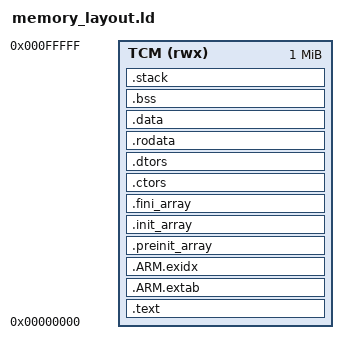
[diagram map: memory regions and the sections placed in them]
/****************************************************************************
 *                                                                          *
 *                         GNAT COMPILER COMPONENTS                         *
 *                                                                          *
 *                                  A R M                                   *
 *                                                                          *
 *                            Linker Script File                            *
 *                                                                          *
 *      Copyright (C) 1999-2002 Universidad Politecnica de Madrid           *
 *             Copyright (C) 2003-2006 The European Space Agency            *
 *                   Copyright (C) 2003-2018 AdaCore                        *
 *                                                                          *
 * GNAT is free software;  you can  redistribute it  and/or modify it under *
 * terms of the  GNU General Public License as published  by the Free Soft- *
 * ware  Foundation;  either version 2,  or (at your option) any later ver- *
 * sion.  GNAT is distributed in the hope that it will be useful, but WITH- *
 * OUT ANY WARRANTY;  without even the  implied warranty of MERCHANTABILITY *
 * or FITNESS FOR A PARTICULAR PURPOSE.  See the GNU General Public License *
 * for  more details.  You should have  received  a copy of the GNU General *
 * Public License  distributed with GNAT;  see file COPYING.  If not, write *
 * to  the  Free Software Foundation,  51  Franklin  Street,  Fifth  Floor, *
 * Boston, MA 02110-1301, USA.                                              *
 *                                                                          *
 * As a  special  exception,  if you  link  this file  with other  files to *
 * produce an executable,  this file does not by itself cause the resulting *
 * executable to be covered by the GNU General Public License. This except- *
 * ion does not  however invalidate  any other reasons  why the  executable *
 * file might be covered by the  GNU Public License.                        *
 *                                                                          *
 * GNARL was developed by the GNARL team at Florida State University.       *
 * Extensive contributions were provided by Ada Core Technologies, Inc.     *
 * The  executive  was developed  by the  Real-Time  Systems  Group  at the *
 * Technical University of Madrid.                                          *
 *                                                                          *
 ****************************************************************************/

ENTRY(reset_handler);

WORD_SIZE = 4;

MEMORY
{
  TCM(rwx) : ORIGIN = 0x00000000, LENGTH = 1024K
}

SECTIONS
{
 .text :
  {
    __mpu_global_text_region_start = .;

    KEEP (*(.text.hidden.interrupt_vector_table))

    *(.text.hidden.*)

    __hidden_text_end = .;
    __mpu_hidden_text_region_end = .;

    PROVIDE (_text_start = .);

   /* Functions that are the only ones allowed to enter privileged mode */
    __syscall_functions_start = .;
    *(.text.syscall.*)
    __syscall_functions_end = .;

    *(.text.unlikely .text.unlikely.*)
    *(.text.startup .text.startup.*)
    *(.text .text.*)
    *(.gnu.linkonce.t.*)
  } >TCM

  PROVIDE (__etext = .);
  PROVIDE (_etext = .);
  PROVIDE (etext = .);

  /*
   * ARM exception unwind table
   */
  .ARM.extab :
  {
    *(.ARM.extab* .gnu.linkonce.armextab.*)
  } >TCM

  /*
   * ARM exception unwind table index
   */
  .ARM.exidx :
  {
    PROVIDE_HIDDEN (__exidx_start = .);
    *(.ARM.exidx* .gnu.linkonce.armexidx.*)
    PROVIDE_HIDDEN (__exidx_end = .);
  } >TCM

  .preinit_array :
  {
    PROVIDE_HIDDEN (__preinit_array_start = .);
    KEEP (*(.preinit_array))
    PROVIDE_HIDDEN (__preinit_array_end = .);
  } >TCM

  .init_array :
  {
    PROVIDE_HIDDEN (__init_array_start = .);
    KEEP (*(SORT_BY_INIT_PRIORITY(.init_array.*) SORT_BY_INIT_PRIORITY(.ctors.*)))
    KEEP (*(.init_array EXCLUDE_FILE (*crtbegin.o *crtbegin?.o *crtend.o *crtend?.o ) .ctors))
    PROVIDE_HIDDEN (__init_array_end = .);
  } >TCM

  .fini_array :
  {
    PROVIDE_HIDDEN (__fini_array_start = .);
    KEEP (*(SORT_BY_INIT_PRIORITY(.fini_array.*) SORT_BY_INIT_PRIORITY(.dtors.*)))
    KEEP (*(.fini_array EXCLUDE_FILE (*crtbegin.o *crtbegin?.o *crtend.o *crtend?.o ) .dtors))
    PROVIDE_HIDDEN (__fini_array_end = .);
  } >TCM

  .ctors :
  {
    /* gcc uses crtbegin.o to find the start of
       the constructors, so we make sure it is
       first.  Because this is a wildcard, it
       doesn't matter if the user does not
       actually link against crtbegin.o; the
       linker won't look for a file to match a
       wildcard.  The wildcard also means that it
       doesn't matter which directory crtbegin.o
       is in.  */
    KEEP (*crtbegin.o(.ctors))
    KEEP (*crtbegin?.o(.ctors))
    /* We don't want to include the .ctor section from
       the crtend.o file until after the sorted ctors.
       The .ctor section from the crtend file contains the
       end of ctors marker and it must be last */
    KEEP (*(EXCLUDE_FILE (*crtend.o *crtend?.o ) .ctors))
    KEEP (*(SORT(.ctors.*)))
    KEEP (*(.ctors))
  } >TCM

  .dtors :
  {
    KEEP (*crtbegin.o(.dtors))
    KEEP (*crtbegin?.o(.dtors))
    KEEP (*(EXCLUDE_FILE (*crtend.o *crtend?.o ) .dtors))
    KEEP (*(SORT(.dtors.*)))
    KEEP (*(.dtors))
  } >TCM

  PROVIDE (_text_end = .);

  .rodata :
  {
    PROVIDE_HIDDEN (__rodata_start = .);
    *(.rdata)
    *(.rodata .rodata.*)
    *(.gnu.linkonce.r.*)
    PROVIDE_HIDDEN (__rodata_end = .);
  } >TCM

  . = ALIGN(WORD_SIZE);
  PROVIDE( __data_load = . );

  __mpu_global_text_region_end = .;

  .data :  AT (__data_load)
  {
  . = ALIGN(WORD_SIZE);
    __mpu_global_data_region_start = .;
    PROVIDE( _data = . );
    *(.data .data.*)
    *(.gnu.linkonce.d.*)
    *(.sdata .sdata.*)
    *(.sdata2 .sdata2.*)
    *(.gnu.linkonce.s.*)
    *(.srodata.cst16)
    *(.srodata.cst8)
    *(.srodata.cst4)
    *(.srodata.cst2)
    *(.srodata .srodata.*)

    /*
     * Hidden initialized global variables (not accessible by default)
     * are located at the end of the data section
     */
    __mpu_hidden_data_region_start = .;
    __hidden_data_and_bss_start = .;
    __hidden_data_start = .;
    *(.hidden_data)
    __hidden_data_end = .;
  } >TCM

  PROVIDE( _edata = . );
  PROVIDE( edata = . );

  PROVIDE( __bss_start = . );
  .bss (NOLOAD)  :
  {
    . = ALIGN(WORD_SIZE);
   /*
    * Hidden uninitialized global variables (not accessible by default)
    * are located the beginning of the bss section
    */
    __hidden_bss_start = .;
    *(.hidden_bss)
    __hidden_bss_end = .;
    __hidden_data_and_bss_end = .;
    __mpu_hidden_data_region_end = .;

    *(.sbss*)
    *(.gnu.linkonce.sb.*)
    *(.bss .bss.*)
    *(.gnu.linkonce.b.*)
    *(COMMON)
  } >TCM

  PROVIDE( __bss_end = . );

  __mpu_global_data_region_end = .;

  /*
   * NOTE: the ISR stack is allocated before (lower in memory) the thread stacks,
   * so that in case of ISR stack overflow, the thread stacks are not corrupted.
   * A thread stack overflow cannot corrupt the ISR stack, as a thread never
   * preempts an ISR. A thread stack overflow can corrupt another thread stack,
   * if the thread with stack overflow is running in privileged mode, unless
   * stack guard regions are placed in fron of each stack.
   */
  .stack (NOLOAD)  :
  {
    _stacks_start = .;
    *(.isr_stack)
    *(.thread_stacks)
    _stacks_end = .;
  } >TCM
}
